# ATSAMRH707F18A device description
Architecture: CORTEX-M7; Family: SAMRH; Series: SAMRH707
Registers are 32-bit, read-write, no defined reset value unless marked. A register's access mark holds for its fields unless they carry their own. Offsets are from the block's base; [hi:lo] are bit positions; 'fields as' and 'values as' point back to an identical list.

## TCMECC
Instances: TCMECC 0x40100400
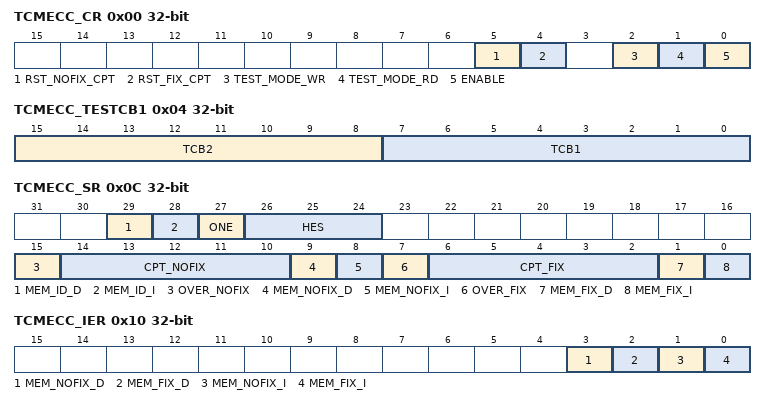
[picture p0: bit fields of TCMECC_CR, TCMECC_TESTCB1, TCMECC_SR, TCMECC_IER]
0x00 TCMECC_CR — TCMECC Control Register
  [5] RST_NOFIX_CPT — reset the un-fixable error counter
  [4] RST_FIX_CPT — reset the fixable error counter
  [2] TEST_MODE_WR — test mode of ECC protection - write mode
  [1] TEST_MODE_RD — test mode of ECC protection - read mode
  [0] ENABLE — ECC protection enable
0x04 TCMECC_TESTCB1 — TCMECC Test mode register 1
  [15:8] TCB2 — test check bit (8 bit)
  [7:0] TCB1 — test check bit (8 bit)
0x0C TCMECC_SR ro — TCMECC Status register
  [29] MEM_ID_D — memory identification number
  [28] MEM_ID_I — memory identification number
  [27] ONE
  [26:24] HES — Hardware Error Size
  [15] OVER_NOFIX — counter overflow
  [14:10] CPT_NOFIX — 5 bits counter
  [9] MEM_NOFIX_D — Un-fixable error status in data memory
  [8] MEM_NOFIX_I — Un-fixable error status in instruction memory
  [7] OVER_FIX — counter overflow
  [6:2] CPT_FIX — 5 bits counter
  [1] MEM_FIX_D — Fixable error status in data memory
  [0] MEM_FIX_I — Fixable error status in instruction memory
0x10 TCMECC_IER wo — TCMECC Interrupt Enable Register
  [3] MEM_NOFIX_D — Un-fixable error on data
  [2] MEM_FIX_D — Fixable error on data
  [1] MEM_NOFIX_I — Un-fixable error on instruction
  [0] MEM_FIX_I — Fixable error on instruction
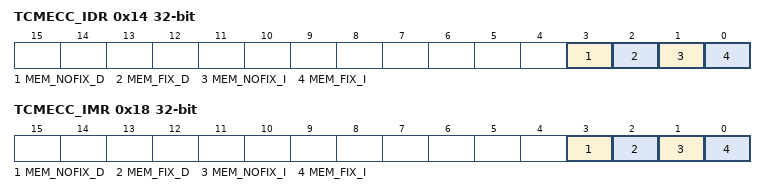
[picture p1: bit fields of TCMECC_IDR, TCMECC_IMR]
0x14 TCMECC_IDR wo — TCMECC Interrupt Disable Register
  [3] MEM_NOFIX_D — un-fixable error on data
  [2] MEM_FIX_D — fixable error on data
  [1] MEM_NOFIX_I — un-fixable error on instruction
  [0] MEM_FIX_I — fixable error on instruction
0x18 TCMECC_IMR ro — TCMECC Interrupt Mask Register
  fields as TCMECC_IDR
0x1C TCMECC_FAILAR ro — TCMECC Fail address register
  [31:0] ADDRESS — address of the error detected (refers to instruction memory)
0x20 TCMECC_FAILARD ro — TCMECC Fail address register data
  [31:0] ADDRESS — address of the error detected
0x24 TCMECC_FAILDR ro — TCMECC Fail data register
  [31:0] DATA — data of the error detected (refers to instruction memory)
0x28 TCMECC_FAILDRD ro — TCMECC Fail data register data
  fields as TCMECC_FAILDR

## TRNG — True Random Number Generator
Instances: TRNG 0x40090000
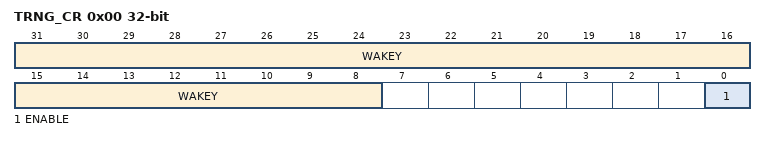
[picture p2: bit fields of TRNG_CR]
0x00 TRNG_CR wo — Control Register
  [31:8] WAKEY — Register Write Access Key
    0x524E47=PASSWD (Writing any other value in this field aborts the write operation.)
  [0] ENABLE — Enables the TRNG to Provide Random Values
0x10 TRNG_IER wo — Interrupt Enable Register
  [0] DATRDY — Data Ready Interrupt Enable
0x14 TRNG_IDR wo — Interrupt Disable Register
  [0] DATRDY — Data Ready Interrupt Disable
0x18 TRNG_IMR ro — Interrupt Mask Register
  [0] DATRDY — Data Ready Interrupt Mask
0x1C TRNG_ISR ro — Interrupt Status Register
  [0] DATRDY — Data Ready (cleared on read)
0x50 TRNG_ODATA ro — Output Data Register
  [31:0] ODATA — Output Data

## WDT — Watchdog Timer
Instances: WDT 0x40100250
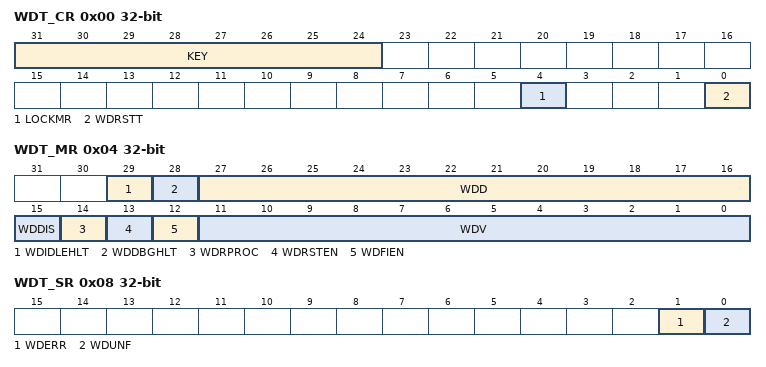
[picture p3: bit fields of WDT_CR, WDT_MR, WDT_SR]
0x00 WDT_CR wo — Control Register
  [31:24] KEY — Password
    165=PASSWD (Writing any other value in this field aborts the write operation.)
  [4] LOCKMR — Lock Mode Register Write Access
  [0] WDRSTT — Watchdog Restart
0x04 WDT_MR — Mode Register
  [29] WDIDLEHLT — Watchdog Idle Halt
  [28] WDDBGHLT — Watchdog Debug Halt
  [27:16] WDD — Watchdog Delta Value
  [15] WDDIS — Watchdog Disable
  [14] WDRPROC — Watchdog Reset Processor
  [13] WDRSTEN — Watchdog Reset Enable
  [12] WDFIEN — Watchdog Fault Interrupt Enable
  [11:0] WDV — Watchdog Counter Value
0x08 WDT_SR ro — Status Register
  [1] WDERR — Watchdog Error (cleared on read)
  [0] WDUNF — Watchdog Underflow (cleared on read)

## GPNVMBITS (FUSES module)
Instances: GPNVMBITS 0 in fuses
0x00 USER_WORD_0 ro — USER Page Word 0. Contains factory setting values, do no override.
  [31:0] RC_TRIM_CRC
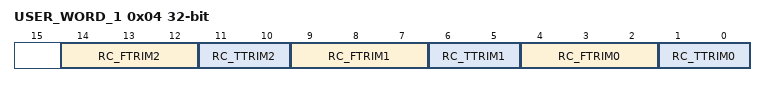
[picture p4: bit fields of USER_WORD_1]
0x04 USER_WORD_1 ro — USER Page Word 1. Contains factory setting values, do no override.
  [14:12] RC_FTRIM2 — RC Frequency Trim 2
  [11:10] RC_TTRIM2 — RC Temperature Trim 2
  [9:7] RC_FTRIM1 — RC Frequency Trim 1
  [6:5] RC_TTRIM1 — RC Temperature Trim 1
  [4:2] RC_FTRIM0 — RC Frequency Trim 0
  [1:0] RC_TTRIM0 — RC Temperature Trim 0
0x08 USER_WORD_2 ro — USER Page Word 2. Contains factory setting values, do no override.
  [31:0] USR_WORD2 — USER Word 2
0x0C USER_WORD_3 ro — USER Page Word 3. Contains factory setting values, do no override.
  [31:0] USR_WORD3 — USER Word 3
